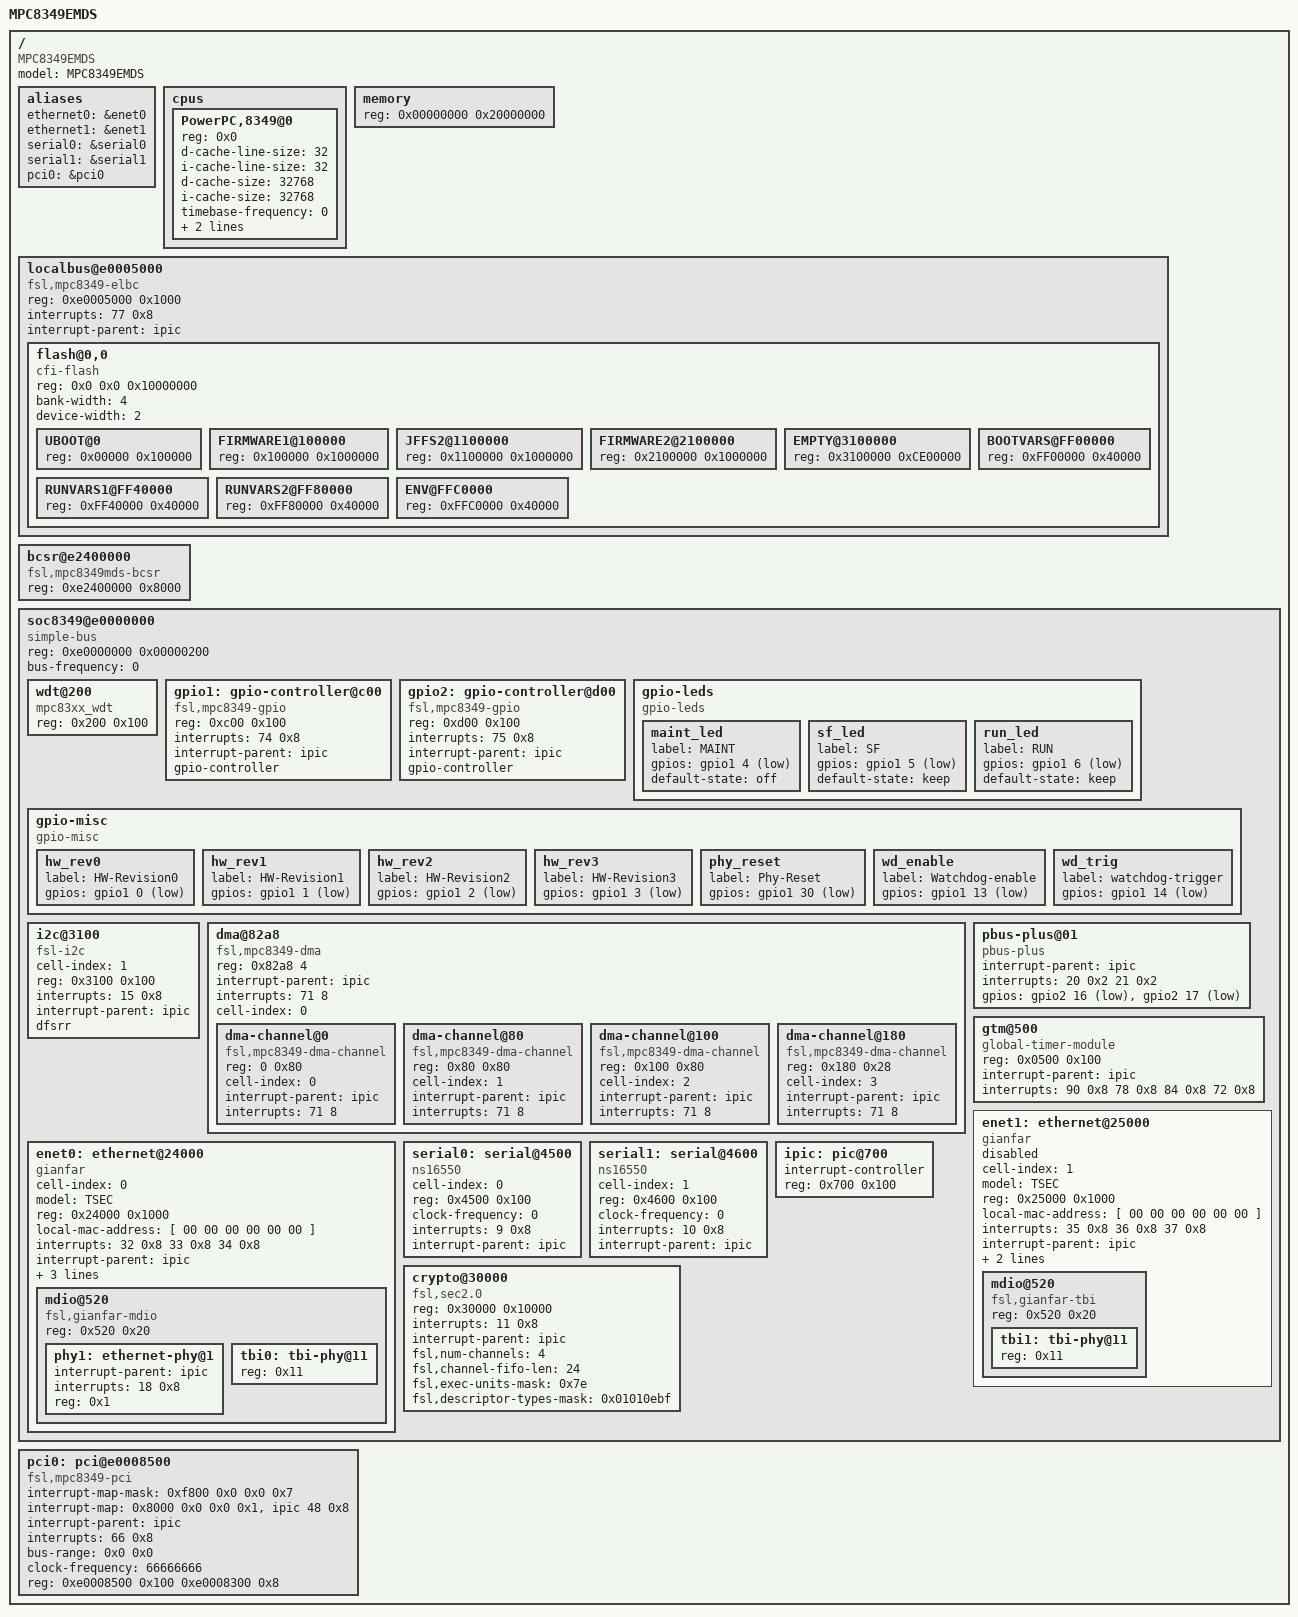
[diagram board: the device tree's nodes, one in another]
/*
 * MPC8349E MDS Device Tree Source
 *
 * Copyright 2005, 2006 Freescale Semiconductor Inc.
 *
 * This program is free software; you can redistribute  it and/or modify it
 * under  the terms of  the GNU General  Public License as published by the
 * Free Software Foundation;  either version 2 of the  License, or (at your
 * option) any later version.
 */

/dts-v1/;

/ {
	model = "MPC8349EMDS";
	compatible = "MPC8349EMDS", "MPC834xMDS", "MPC83xxMDS";
	#address-cells = <1>;
	#size-cells = <1>;

	aliases {
		ethernet0 = &enet0;
		ethernet1 = &enet1; 
		serial0 = &serial0;
		serial1 = &serial1;
		pci0 = &pci0;
	};

	cpus {
		#address-cells = <1>;
		#size-cells = <0>;

		PowerPC,8349@0 {
			device_type = "cpu";
			reg = <0x0>;
			d-cache-line-size = <32>;
			i-cache-line-size = <32>;
			d-cache-size = <32768>;
			i-cache-size = <32768>;
			timebase-frequency = <0>;	// from bootloader
			bus-frequency = <0>;		// from bootloader
			clock-frequency = <0>;		// from bootloader
		};
	};

	memory {
		device_type = "memory";
		reg = <0x00000000 0x20000000>;	/* 512 MB at 0 */
	};

	localbus@e0005000 { 
                #address-cells = <2>; 
                #size-cells = <1>; 
                compatible = "fsl,mpc8349-elbc", "fsl,elbc", "simple-bus"; 
                reg = <0xe0005000 0x1000>; 
                interrupts = <77 0x8>; 
                interrupt-parent = <&ipic>; 

		/* CS0: Onboard NOR Flash 256 MB */
                ranges = <0x0 0x0 0xf0000000 0x10000000>; 

                flash@0,0 { 
                        #address-cells = <1>; 
                        #size-cells = <1>; 
                        compatible = "cfi-flash"; 
                        reg = <0x0 0x0 0x10000000>; 
                        bank-width = <4>;
                        device-width = <2>; 

                        UBOOT@0 {
                                reg = <0x00000 0x100000>;     /* mtd0 1 MB */
                        }; 

                        FIRMWARE1@100000 {
                                reg = <0x100000 0x1000000>;   /* mtd1 16 MB */
                        }; 

                        JFFS2@1100000 {
                                reg = <0x1100000 0x1000000>;  /* mtd2 16 MB */ 
                        }; 

                        FIRMWARE2@2100000 {
                                reg = <0x2100000 0x1000000>;  /* mtd3 16 MB */
                        }; 

                        EMPTY@3100000 {
                                reg = <0x3100000 0xCE00000>;  /* mtd4 206 MB */
                        }; 

                        BOOTVARS@FF00000 {
                                reg = <0xFF00000 0x40000>;    /* mtd5 256 KB */
                        };
                         
                        RUNVARS1@FF40000 {
                                reg = <0xFF40000 0x40000>;    /* mtd6 256 KB */
                        };
                        
                        RUNVARS2@FF80000 {
                                reg = <0xFF80000 0x40000>;    /* mtd7 256 KB */
                        }; 
                         
                        ENV@FFC0000 {                       
                                reg = <0xFFC0000 0x40000>;    /* mtd8 256 KB UBOOT ENV*/
				//read-only;
                        }; 
                }; 
        }; 

	bcsr@e2400000 {
		compatible = "fsl,mpc8349mds-bcsr";
		reg = <0xe2400000 0x8000>;
	};

	soc8349@e0000000 {
		#address-cells = <1>;
		#size-cells = <1>;
		device_type = "soc";
		compatible = "simple-bus";
		ranges = <0x0 0xe0000000 0x00100000>;
		reg = <0xe0000000 0x00000200>;
		bus-frequency = <0>;

		wdt@200 {
			device_type = "watchdog";
			compatible = "mpc83xx_wdt";
			reg = <0x200 0x100>;
		};

		gpio1: gpio-controller@c00 {
			#gpio-cells = <2>;
			compatible = "fsl,mpc8349-gpio";
			reg = <0xc00 0x100>;
			interrupts = <74 0x8>;
			interrupt-parent = <&ipic>;
			gpio-controller;
		};

		gpio2: gpio-controller@d00 {
			#gpio-cells = <2>;
			compatible = "fsl,mpc8349-gpio";
			reg = <0xd00 0x100>;
			interrupts = <75 0x8>;
			interrupt-parent = <&ipic>;
			gpio-controller;
		};

		gpio-leds {
			compatible = "gpio-leds";

			maint_led {
				label = "MAINT";
				gpios = <&gpio1 4 1>;
				default-state = "off"; /* keep, off, on, timer */
			};
			sf_led {
				label = "SF";
				gpios = <&gpio1 5 1>;
				default-state = "keep"; /* keep, off, on, timer */
			};
			run_led {
				label = "RUN";
				gpios = <&gpio1 6 1>;
				default-state = "keep"; /* keep, off, on, timer */
			};
		};

		gpio-misc {
			compatible = "gpio-misc";

			hw_rev0 {
				label = "HW-Revision0";
				gpios = <&gpio1 0 1>;
			};
			hw_rev1 {
				label = "HW-Revision1";
				gpios = <&gpio1 1 1>;
			};
			hw_rev2 {
				label = "HW-Revision2";
				gpios = <&gpio1 2 1>;
			};
			hw_rev3 {
				label = "HW-Revision3";
				gpios = <&gpio1 3 1>;
			};
			phy_reset {
				label = "Phy-Reset";
				gpios = <&gpio1 30 1>;
			};
			wd_enable {
				label = "Watchdog-enable";
				gpios = <&gpio1 13 1>;
			};
			wd_trig{
				label = "watchdog-trigger";
				gpios = <&gpio1 14 1>;
			};
		};

/*
		i2c@3000 {
			#address-cells = <1>;
			#size-cells = <0>;
			cell-index = <0>;
			compatible = "fsl-i2c";
			reg = <0x3000 0x100>;
			interrupts = <14 0x8>;
			interrupt-parent = <&ipic>;
			dfsrr;

			rtc@68 {
				compatible = "dallas,ds1374";
				reg = <0x68>;
			};
		};
*/

		i2c@3100 {
			#address-cells = <1>;
			#size-cells = <0>;
			cell-index = <1>;
			compatible = "fsl-i2c";
			reg = <0x3100 0x100>;
			interrupts = <15 0x8>;
			interrupt-parent = <&ipic>;
			dfsrr;
		};
/*
		spi@7000 {
			cell-index = <0>;
			compatible = "fsl,spi";
			reg = <0x7000 0x1000>;
			interrupts = <16 0x8>;
			interrupt-parent = <&ipic>;
			mode = "cpu";
		};
*/
		dma@82a8 {
			#address-cells = <1>;
			#size-cells = <1>;
			compatible = "fsl,mpc8349-dma", "fsl,elo-dma";
			reg = <0x82a8 4>;
			ranges = <0 0x8100 0x1a8>;
			interrupt-parent = <&ipic>;
			interrupts = <71 8>;
			cell-index = <0>;
			dma-channel@0 {
				compatible = "fsl,mpc8349-dma-channel", "fsl,elo-dma-channel";
				reg = <0 0x80>;
				cell-index = <0>;
				interrupt-parent = <&ipic>;
				interrupts = <71 8>;
			};
			dma-channel@80 {
				compatible = "fsl,mpc8349-dma-channel", "fsl,elo-dma-channel";
				reg = <0x80 0x80>;
				cell-index = <1>;
				interrupt-parent = <&ipic>;
				interrupts = <71 8>;
			};
			dma-channel@100 {
				compatible = "fsl,mpc8349-dma-channel", "fsl,elo-dma-channel";
				reg = <0x100 0x80>;
				cell-index = <2>;
				interrupt-parent = <&ipic>;
				interrupts = <71 8>;
			};
			dma-channel@180 {
				compatible = "fsl,mpc8349-dma-channel", "fsl,elo-dma-channel";
				reg = <0x180 0x28>;
				cell-index = <3>;
				interrupt-parent = <&ipic>;
				interrupts = <71 8>;
			};
		};

		/* phy type (ULPI or SERIAL) are only types supported for MPH */
		/* port = 0 or 1 */
/*
		usb@22000 {
			compatible = "fsl-usb2-mph";
			reg = <0x22000 0x1000>;
			#address-cells = <1>;
			#size-cells = <0>;
			interrupt-parent = <&ipic>;
			interrupts = <39 0x8>;
			phy_type = "ulpi";
			port0;
		};
*/
		/* phy type (ULPI, UTMI, UTMI_WIDE, SERIAL) */
/*
		usb@23000 {
			compatible = "fsl-usb2-dr";
			reg = <0x23000 0x1000>;
			#address-cells = <1>;
			#size-cells = <0>;
			interrupt-parent = <&ipic>;
			interrupts = <38 0x8>;
			dr_mode = "otg";
			phy_type = "ulpi";
		};
*/
		pbus-plus@01 {
			compatible = "pbus-plus";
			interrupt-parent = <&ipic>;
			interrupts = <20 0x2 21 0x2>;
			gpios = <&gpio2 16 1
				 &gpio2 17 1>;
		};

		gtm@500 {
			compatible = "global-timer-module";
			reg = <0x0500 0x100>;
			interrupt-parent = <&ipic>;
			interrupts = <90 0x8 78 0x8 84 0x8 72 0x8>;
		};

		enet0: ethernet@24000 {
			#address-cells = <1>;
			#size-cells = <1>;
			cell-index = <0>;
			device_type = "network";
			model = "TSEC";
			compatible = "gianfar";
			reg = <0x24000 0x1000>;
			ranges = <0x0 0x24000 0x1000>;
			local-mac-address = [ 00 00 00 00 00 00 ];
			interrupts = <32 0x8 33 0x8 34 0x8>;
			interrupt-parent = <&ipic>;
			tbi-handle = <&tbi0>;
			phy-handle = <&phy1>;
			linux,network-index = <0>;

			mdio@520 {
				#address-cells = <1>;
				#size-cells = <0>;
				compatible = "fsl,gianfar-mdio";
				reg = <0x520 0x20>;

				/*phy0: ethernet-phy@0 {
					interrupt-parent = <&ipic>;
					interrupts = <17 0x8>;
					reg = <0x0>;
					device_type = "ethernet-phy";
				};*/

				phy1: ethernet-phy@1 {
					interrupt-parent = <&ipic>;
					interrupts = <18 0x8>;
					reg = <0x1>;
					device_type = "ethernet-phy";
				};

				tbi0: tbi-phy@11 {
					reg = <0x11>;
					device_type = "tbi-phy";
				};
			};
		};

		enet1: ethernet@25000 {
			#address-cells = <1>;
			#size-cells = <1>;
			cell-index = <1>;
			device_type = "network";
			model = "TSEC";
			compatible = "gianfar";
			reg = <0x25000 0x1000>;
			ranges = <0x0 0x25000 0x1000>;
			local-mac-address = [ 00 00 00 00 00 00 ];
			interrupts = <35 0x8 36 0x8 37 0x8>;
			interrupt-parent = <&ipic>;
			tbi-handle = <&tbi1>;
			/*phy-handle = <&phy0>;*/
			linux,network-index = <1>;
			status = "disabled";

			mdio@520 {
				#address-cells = <1>;
				#size-cells = <0>;
				compatible = "fsl,gianfar-tbi";
				reg = <0x520 0x20>;

				tbi1: tbi-phy@11 {
					reg = <0x11>;
					device_type = "tbi-phy";
				};
			};
		};

		serial0: serial@4500 {
			cell-index = <0>;
			device_type = "serial";
			compatible = "ns16550";
			reg = <0x4500 0x100>;
			clock-frequency = <0>;
			interrupts = <9 0x8>;
			interrupt-parent = <&ipic>;
		};

		serial1: serial@4600 {
			cell-index = <1>;
			device_type = "serial";
			compatible = "ns16550";
			reg = <0x4600 0x100>;
			clock-frequency = <0>;
			interrupts = <10 0x8>;
			interrupt-parent = <&ipic>;
		};

		crypto@30000 {
			compatible = "fsl,sec2.0";
			reg = <0x30000 0x10000>;
			interrupts = <11 0x8>;
			interrupt-parent = <&ipic>;
			fsl,num-channels = <4>;
			fsl,channel-fifo-len = <24>;
			fsl,exec-units-mask = <0x7e>;
			fsl,descriptor-types-mask = <0x01010ebf>;
		};

		/* IPIC
		 * interrupts cell = <intr #, sense>
		 * sense values match linux IORESOURCE_IRQ_* defines:
		 * sense == 8: Level, low assertion
		 * sense == 2: Edge, high-to-low change
		 */
		ipic: pic@700 {
			interrupt-controller;
			#address-cells = <0>;
			#interrupt-cells = <2>;
			reg = <0x700 0x100>;
			device_type = "ipic";
		};
	};

	pci0: pci@e0008500 {
		interrupt-map-mask = <0xf800 0x0 0x0 0x7>;
		interrupt-map = <
				/* IDSEL 0x10 - MS-ASIC */
				0x8000 0x0 0x0 0x1 &ipic 48 0x8 

				>;
		interrupt-parent = <&ipic>;
		interrupts = <66 0x8>;
		bus-range = <0x0 0x0>;
		ranges = <0x02000000 0x0 0x80000000 0x80000000 0x0 0x10000000
			  0x42000000 0x0 0x90000000 0x90000000 0x0 0x10000000
			  0x01000000 0x0 0x00000000 0xe2000000 0x0 0x00100000>;

		clock-frequency = <66666666>;
		#interrupt-cells = <1>;
		#size-cells = <2>;
		#address-cells = <3>;
		reg = <0xe0008500 0x100		/* internal registers */
		       0xe0008300 0x8>;		/* config space access registers */
		compatible = "fsl,mpc8349-pci";
		device_type = "pci";
	};

};
